# f28p65x_pctrace_buffer_regs register map
Vendor: Texas Instruments
Peripheral module from a debugger description file (folder C2000).
Address unit: 16 bits
Registers are 32-bit, read-only, no defined reset value unless marked. A register's access mark holds for its fields unless they carry their own. Offsets are as the file gives them; lines under a group give offsets from that group; [hi:lo] are bit positions; {n}, {i} and the like mark numbered series; 'fields as' and 'values as' point back to an identical list; <NAME> marks a mode.

## PCTRACE_BUFFER_REGS — PCTRACE BUFFER Registers
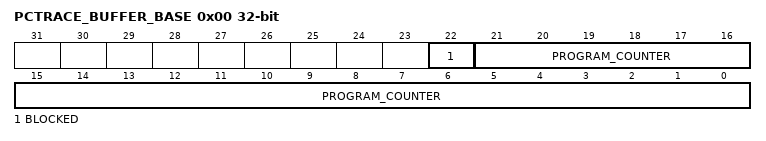
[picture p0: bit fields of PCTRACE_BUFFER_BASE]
0x00 PCTRACE_BUFFER_BASE
  [22] BLOCKED — Access blocked due to security
  [21:0] PROGRAM_COUNTER
